# STM32H743x register map
File version: 1.0
CPU: CM7 r0p1, little endian, MPU, FPU, 4 interrupt priority bits
Registers are 32-bit, read-write, reset 0x0 unless marked. A register's access mark holds for its fields unless they carry their own. Offsets are from the block's base; [hi:lo] are bit positions; {n}, {i} and the like mark numbered series; 'fields as' and 'values as' point back to an identical list.

## RTC
Base 0x58004000
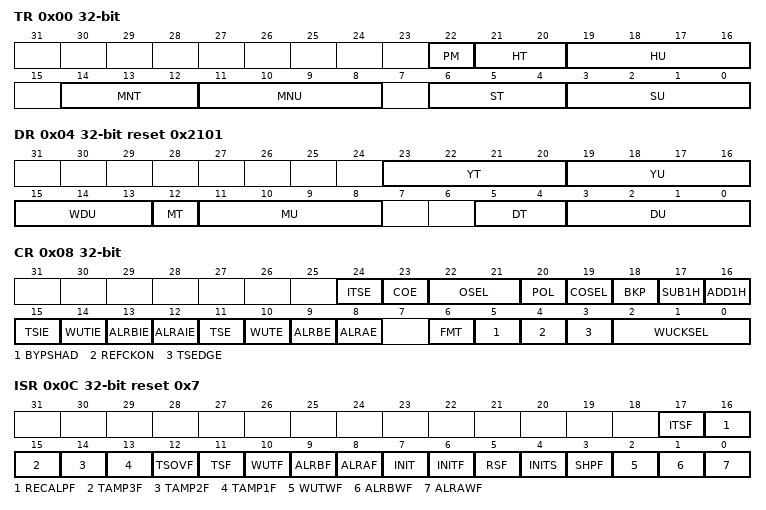
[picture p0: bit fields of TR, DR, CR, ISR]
0x00 TR — The RTC_TR is the calendar time shadow register. This register must be written in initialization mode only. Refer to Calendar initialization and configuration on page9 and Reading the calendar on page10.This register is write protected. The write access procedure is described in RTC register write protection on page9.
  [22] PM — AM/PM notation
  [21:20] HT — Hour tens in BCD format
  [19:16] HU — Hour units in BCD format
  [14:12] MNT — Minute tens in BCD format
  [11:8] MNU — Minute units in BCD format
  [6:4] ST — Second tens in BCD format
  [3:0] SU — Second units in BCD format
0x04 DR reset 0x2101 — The RTC_DR is the calendar date shadow register. This register must be written in initialization mode only. Refer to Calendar initialization and configuration on page9 and Reading the calendar on page10.This register is write protected. The write access procedure is described in RTC register write protection on page9.
  [23:20] YT — Year tens in BCD format
  [19:16] YU — Year units in BCD format
  [15:13] WDU — Week day units
  [12] MT — Month tens in BCD format
  [11:8] MU — Month units in BCD format
  [5:4] DT — Date tens in BCD format
  [3:0] DU — Date units in BCD format
0x08 CR access per field — RTC control register
  [24] ITSE rw — timestamp on internal event enable
  [23] COE rw — Calibration output enable This bit enables the RTC_CALIB output
  [22:21] OSEL rw — Output selection These bits are used to select the flag to be routed to RTC_ALARM output
  [20] POL rw — Output polarity This bit is used to configure the polarity of RTC_ALARM output
  [19] COSEL rw — Calibration output selection When COE=1, this bit selects which signal is output on RTC_CALIB. These frequencies are valid for RTCCLK at 32.768 kHz and prescalers at their default values (PREDIV_A=127 and PREDIV_S=255). Refer to Section24.3.15: Calibration clock output
  [18] BKP rw — Backup This bit can be written by the user to memorize whether the daylight saving time change has been performed or not.
  [17] SUB1H wo — Subtract 1 hour (winter time change) When this bit is set outside initialization mode, 1 hour is subtracted to the calendar time if the current hour is not 0. This bit is always read as 0. Setting this bit has no effect when current hour is 0.
  [16] ADD1H wo — Add 1 hour (summer time change) When this bit is set outside initialization mode, 1 hour is added to the calendar time. This bit is always read as 0.
  [15] TSIE rw — Time-stamp interrupt enable
  [14] WUTIE rw — Wakeup timer interrupt enable
  [13] ALRBIE rw — Alarm B interrupt enable
  [12] ALRAIE rw — Alarm A interrupt enable
  [11] TSE rw — timestamp enable
  [10] WUTE rw — Wakeup timer enable
  [9] ALRBE rw — Alarm B enable
  [8] ALRAE rw — Alarm A enable
  [6] FMT rw — Hour format
  [5] BYPSHAD rw — Bypass the shadow registers Note: If the frequency of the APB clock is less than seven times the frequency of RTCCLK, BYPSHAD must be set to 1.
  [4] REFCKON rw — RTC_REFIN reference clock detection enable (50 or 60Hz) Note: PREDIV_S must be 0x00FF.
  [3] TSEDGE rw — Time-stamp event active edge TSE must be reset when TSEDGE is changed to avoid unwanted TSF setting.
  [2:0] WUCKSEL rw — Wakeup clock selection
0x0C ISR access per field reset 0x7 — This register is write protected (except for RTC_ISR[13:8] bits). The write access procedure is described in RTC register write protection on page9.
  [17] ITSF rw — Internal tTime-stamp flag
  [16] RECALPF ro — Recalibration pending Flag The RECALPF status flag is automatically set to 1 when software writes to the RTC_CALR register, indicating that the RTC_CALR register is blocked. When the new calibration settings are taken into account, this bit returns to 0. Refer to Re-calibration on-the-fly.
  [15] TAMP3F rw — RTC_TAMP3 detection flag This flag is set by hardware when a tamper detection event is detected on the RTC_TAMP3 input. It is cleared by software writing 0
  [14] TAMP2F rw — RTC_TAMP2 detection flag This flag is set by hardware when a tamper detection event is detected on the RTC_TAMP2 input. It is cleared by software writing 0
  [13] TAMP1F rw — RTC_TAMP1 detection flag This flag is set by hardware when a tamper detection event is detected on the RTC_TAMP1 input. It is cleared by software writing 0
  [12] TSOVF rw — Time-stamp overflow flag This flag is set by hardware when a time-stamp event occurs while TSF is already set. This flag is cleared by software by writing 0. It is recommended to check and then clear TSOVF only after clearing the TSF bit. Otherwise, an overflow might not be noticed if a time-stamp event occurs immediately before the TSF bit is cleared.
  [11] TSF rw — Time-stamp flag This flag is set by hardware when a time-stamp event occurs. This flag is cleared by software by writing 0.
  [10] WUTF rw — Wakeup timer flag This flag is set by hardware when the wakeup auto-reload counter reaches 0. This flag is cleared by software by writing 0. This flag must be cleared by software at least 1.5 RTCCLK periods before WUTF is set to 1 again.
  [9] ALRBF rw — Alarm B flag This flag is set by hardware when the time/date registers (RTC_TR and RTC_DR) match the Alarm B register (RTC_ALRMBR). This flag is cleared by software by writing 0.
  [8] ALRAF rw — Alarm A flag This flag is set by hardware when the time/date registers (RTC_TR and RTC_DR) match the Alarm A register (RTC_ALRMAR). This flag is cleared by software by writing 0.
  [7] INIT rw — Initialization mode
  [6] INITF ro — Initialization flag When this bit is set to 1, the RTC is in initialization state, and the time, date and prescaler registers can be updated.
  [5] RSF rw — Registers synchronization flag This bit is set by hardware each time the calendar registers are copied into the shadow registers (RTC_SSRx, RTC_TRx and RTC_DRx). This bit is cleared by hardware in initialization mode, while a shift operation is pending (SHPF=1), or when in bypass shadow register mode (BYPSHAD=1). This bit can also be cleared by software. It is cleared either by software or by hardware in initialization mode.
  [4] INITS ro — Initialization status flag This bit is set by hardware when the calendar year field is different from 0 (Backup domain reset state).
  [3] SHPF ro — Shift operation pending This flag is set by hardware as soon as a shift operation is initiated by a write to the RTC_SHIFTR register. It is cleared by hardware when the corresponding shift operation has been executed. Writing to the SHPF bit has no effect.
  [2] WUTWF ro — Wakeup timer write flag This bit is set by hardware up to 2 RTCCLK cycles after the WUTE bit has been set to 0 in RTC_CR, and is cleared up to 2 RTCCLK cycles after the WUTE bit has been set to 1. The wakeup timer values can be changed when WUTE bit is cleared and WUTWF is set.
  [1] ALRBWF ro — Alarm B write flag This bit is set by hardware when Alarm B values can be changed, after the ALRBE bit has been set to 0 in RTC_CR. It is cleared by hardware in initialization mode.
  [0] ALRAWF ro — Alarm A write flag This bit is set by hardware when Alarm A values can be changed, after the ALRAE bit has been set to 0 in RTC_CR. It is cleared by hardware in initialization mode.
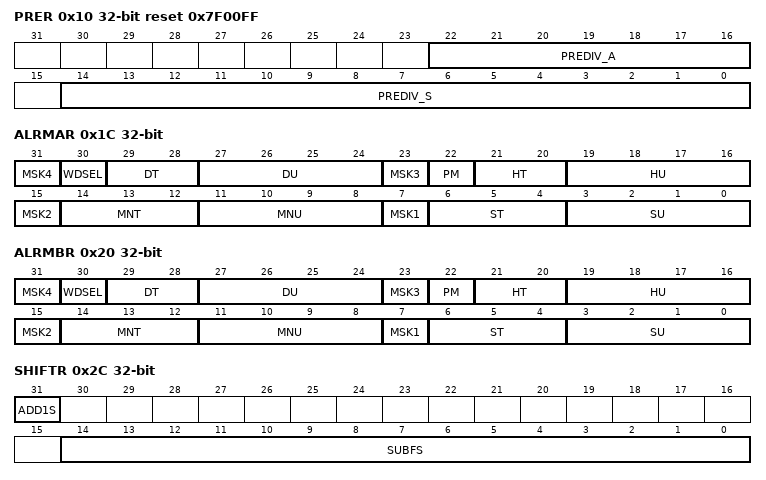
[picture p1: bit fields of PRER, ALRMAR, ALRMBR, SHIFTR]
0x10 PRER reset 0x7F00FF — This register must be written in initialization mode only. The initialization must be performed in two separate write accesses. Refer to Calendar initialization and configuration on page9.This register is write protected. The write access procedure is described in RTC register write protection on page9.
  [22:16] PREDIV_A — Asynchronous prescaler factor This is the asynchronous division factor: ck_apre frequency = RTCCLK frequency/(PREDIV_A+1)
  [14:0] PREDIV_S — Synchronous prescaler factor This is the synchronous division factor: ck_spre frequency = ck_apre frequency/(PREDIV_S+1)
0x14 WUTR reset 0xFFFF — This register can be written only when WUTWF is set to 1 in RTC_ISR.This register is write protected. The write access procedure is described in RTC register write protection on page9.
  [15:0] WUT — Wakeup auto-reload value bits When the wakeup timer is enabled (WUTE set to 1), the WUTF flag is set every (WUT[15:0] + 1) ck_wut cycles. The ck_wut period is selected through WUCKSEL[2:0] bits of the RTC_CR register When WUCKSEL[2] = 1, the wakeup timer becomes 17-bits and WUCKSEL[1] effectively becomes WUT[16] the most-significant bit to be reloaded into the timer. The first assertion of WUTF occurs (WUT+1) ck_wut cycles after WUTE is set. Setting WUT[15:0] to 0x0000 with WUCKSEL[2:0] =011 (RTCCLK/2) is forbidden.
0x1C ALRMAR — This register can be written only when ALRAWF is set to 1 in RTC_ISR, or in initialization mode.This register is write protected. The write access procedure is described in RTC register write protection on page9.
  [31] MSK4 — Alarm A date mask
  [30] WDSEL — Week day selection
  [29:28] DT — Date tens in BCD format.
  [27:24] DU — Date units or day in BCD format.
  [23] MSK3 — Alarm A hours mask
  [22] PM — AM/PM notation
  [21:20] HT — Hour tens in BCD format.
  [19:16] HU — Hour units in BCD format.
  [15] MSK2 — Alarm A minutes mask
  [14:12] MNT — Minute tens in BCD format.
  [11:8] MNU — Minute units in BCD format.
  [7] MSK1 — Alarm A seconds mask
  [6:4] ST — Second tens in BCD format.
  [3:0] SU — Second units in BCD format.
0x20 ALRMBR — This register can be written only when ALRBWF is set to 1 in RTC_ISR, or in initialization mode.This register is write protected. The write access procedure is described in RTC register write protection on page9.
  [31] MSK4 — Alarm B date mask
  [30] WDSEL — Week day selection
  [29:28] DT — Date tens in BCD format
  [27:24] DU — Date units or day in BCD format
  [23] MSK3 — Alarm B hours mask
  [22] PM — AM/PM notation
  [21:20] HT — Hour tens in BCD format
  [19:16] HU — Hour units in BCD format
  [15] MSK2 — Alarm B minutes mask
  [14:12] MNT — Minute tens in BCD format
  [11:8] MNU — Minute units in BCD format
  [7] MSK1 — Alarm B seconds mask
  [6:4] ST — Second tens in BCD format
  [3:0] SU — Second units in BCD format
0x24 WPR wo — RTC write protection register
  [7:0] KEY — Write protection key This byte is written by software. Reading this byte always returns 0x00. Refer to RTC register write protection for a description of how to unlock RTC register write protection.
0x28 SSR ro — RTC sub second register
  [15:0] SS — Sub second value SS[15:0] is the value in the synchronous prescaler counter. The fraction of a second is given by the formula below: Second fraction = (PREDIV_S - SS) / (PREDIV_S + 1) Note: SS can be larger than PREDIV_S only after a shift operation. In that case, the correct time/date is one second less than as indicated by RTC_TR/RTC_DR.
0x2C SHIFTR wo — This register is write protected. The write access procedure is described in RTC register write protection on page9.
  [31] ADD1S — Add one second This bit is write only and is always read as zero. Writing to this bit has no effect when a shift operation is pending (when SHPF=1, in RTC_ISR). This function is intended to be used with SUBFS (see description below) in order to effectively add a fraction of a second to the clock in an atomic operation.
  [14:0] SUBFS — Subtract a fraction of a second These bits are write only and is always read as zero. Writing to this bit has no effect when a shift operation is pending (when SHPF=1, in RTC_ISR). The value which is written to SUBFS is added to the synchronous prescaler counter. Since this counter counts down, this operation effectively subtracts from (delays) the clock by: Delay (seconds) = SUBFS / (PREDIV_S + 1) A fraction of a second can effectively be added to the clock (advancing the clock) when the ADD1S function is used in conjunction with SUBFS, effectively advancing the clock by: Advance (seconds) = (1 - (SUBFS / (PREDIV_S + 1))). Note: Writing to SUBFS causes RSF to be cleared. Software can then wait until RSF=1 to be sure that the shadow registers have been updated with the shifted time.
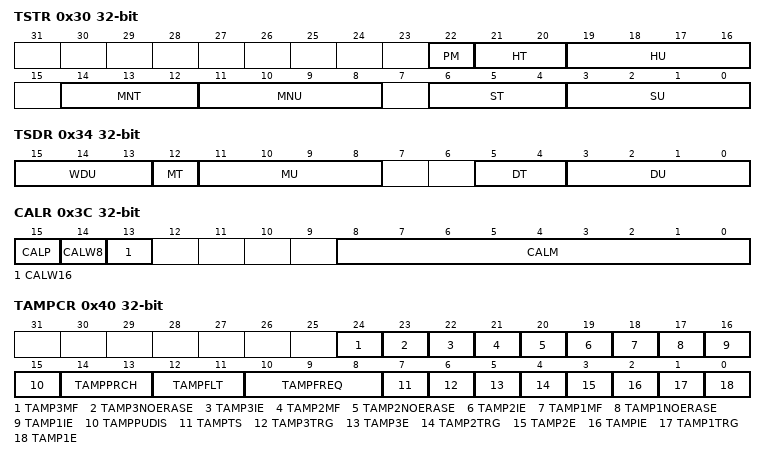
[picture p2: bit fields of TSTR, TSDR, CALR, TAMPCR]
0x30 TSTR ro — The content of this register is valid only when TSF is set to 1 in RTC_ISR. It is cleared when TSF bit is reset.
  [22] PM — AM/PM notation
  [21:20] HT — Hour tens in BCD format.
  [19:16] HU — Hour units in BCD format.
  [14:12] MNT — Minute tens in BCD format.
  [11:8] MNU — Minute units in BCD format.
  [6:4] ST — Second tens in BCD format.
  [3:0] SU — Second units in BCD format.
0x34 TSDR ro — The content of this register is valid only when TSF is set to 1 in RTC_ISR. It is cleared when TSF bit is reset.
  [15:13] WDU — Week day units
  [12] MT — Month tens in BCD format
  [11:8] MU — Month units in BCD format
  [5:4] DT — Date tens in BCD format
  [3:0] DU — Date units in BCD format
0x38 TSSSR ro — The content of this register is valid only when RTC_ISR/TSF is set. It is cleared when the RTC_ISR/TSF bit is reset.
  [15:0] SS — Sub second value SS[15:0] is the value of the synchronous prescaler counter when the timestamp event occurred.
0x3C CALR — This register is write protected. The write access procedure is described in RTC register write protection on page9.
  [15] CALP — Increase frequency of RTC by 488.5 ppm This feature is intended to be used in conjunction with CALM, which lowers the frequency of the calendar with a fine resolution. if the input frequency is 32768 Hz, the number of RTCCLK pulses added during a 32-second window is calculated as follows: (512 * CALP) - CALM. Refer to Section24.3.12: RTC smooth digital calibration.
  [14] CALW8 — Use an 8-second calibration cycle period When CALW8 is set to 1, the 8-second calibration cycle period is selected. Note: CALM[1:0] are stuck at 00; when CALW8= 1. Refer to Section24.3.12: RTC smooth digital calibration.
  [13] CALW16 — Use a 16-second calibration cycle period When CALW16 is set to 1, the 16-second calibration cycle period is selected.This bit must not be set to 1 if CALW8=1. Note: CALM[0] is stuck at 0 when CALW16= 1. Refer to Section24.3.12: RTC smooth digital calibration.
  [8:0] CALM — Calibration minus The frequency of the calendar is reduced by masking CALM out of 220 RTCCLK pulses (32 seconds if the input frequency is 32768 Hz). This decreases the frequency of the calendar with a resolution of 0.9537 ppm. To increase the frequency of the calendar, this feature should be used in conjunction with CALP. See Section24.3.12: RTC smooth digital calibration on page13.
0x40 TAMPCR — RTC tamper and alternate function configuration register
  [24] TAMP3MF — Tamper 3 mask flag
  [23] TAMP3NOERASE — Tamper 3 no erase
  [22] TAMP3IE — Tamper 3 interrupt enable
  [21] TAMP2MF — Tamper 2 mask flag
  [20] TAMP2NOERASE — Tamper 2 no erase
  [19] TAMP2IE — Tamper 2 interrupt enable
  [18] TAMP1MF — Tamper 1 mask flag
  [17] TAMP1NOERASE — Tamper 1 no erase
  [16] TAMP1IE — Tamper 1 interrupt enable
  [15] TAMPPUDIS — RTC_TAMPx pull-up disable This bit determines if each of the RTC_TAMPx pins are pre-charged before each sample.
  [14:13] TAMPPRCH — RTC_TAMPx precharge duration These bit determines the duration of time during which the pull-up/is activated before each sample. TAMPPRCH is valid for each of the RTC_TAMPx inputs.
  [12:11] TAMPFLT — RTC_TAMPx filter count These bits determines the number of consecutive samples at the specified level (TAMP*TRG) needed to activate a Tamper event. TAMPFLT is valid for each of the RTC_TAMPx inputs.
  [10:8] TAMPFREQ — Tamper sampling frequency Determines the frequency at which each of the RTC_TAMPx inputs are sampled.
  [7] TAMPTS — Activate timestamp on tamper detection event TAMPTS is valid even if TSE=0 in the RTC_CR register.
  [6] TAMP3TRG — Active level for RTC_TAMP3 input if TAMPFLT != 00: if TAMPFLT = 00:
  [5] TAMP3E — RTC_TAMP3 detection enable
  [4] TAMP2TRG — Active level for RTC_TAMP2 input if TAMPFLT != 00: if TAMPFLT = 00:
  [3] TAMP2E — RTC_TAMP2 input detection enable
  [2] TAMPIE — Tamper interrupt enable
  [1] TAMP1TRG — Active level for RTC_TAMP1 input If TAMPFLT != 00 if TAMPFLT = 00:
  [0] TAMP1E — RTC_TAMP1 input detection enable
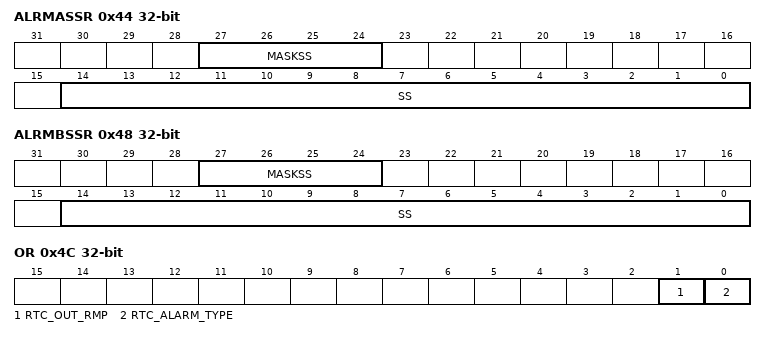
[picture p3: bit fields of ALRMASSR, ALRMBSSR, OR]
0x44 ALRMASSR — This register can be written only when ALRAE is reset in RTC_CR register, or in initialization mode.This register is write protected. The write access procedure is described in RTC register write protection on page9
  [27:24] MASKSS — Mask the most-significant bits starting at this bit ... The overflow bits of the synchronous counter (bits 15) is never compared. This bit can be different from 0 only after a shift operation.
  [14:0] SS — Sub seconds value This value is compared with the contents of the synchronous prescaler counter to determine if Alarm A is to be activated. Only bits 0 up MASKSS-1 are compared.
0x48 ALRMBSSR — This register can be written only when ALRBE is reset in RTC_CR register, or in initialization mode.This register is write protected.The write access procedure is described in Section: RTC register write protection.
  [27:24] MASKSS — Mask the most-significant bits starting at this bit ... The overflow bits of the synchronous counter (bits 15) is never compared. This bit can be different from 0 only after a shift operation.
  [14:0] SS — Sub seconds value This value is compared with the contents of the synchronous prescaler counter to determine if Alarm B is to be activated. Only bits 0 up to MASKSS-1 are compared.
0x4C OR — RTC option register
  [1] RTC_OUT_RMP — RTC_OUT remap
  [0] RTC_ALARM_TYPE — RTC_ALARM output type on PC13
{0x50+4i} BKP{i}R (i=0..7) — RTC backup registers
  [31:0] BKP — The application can write or read data to and from these registers. They are powered-on by VBAT when VDD is switched off, so that they are not reset by System reset, and their contents remain valid when the device operates in low-power mode. This register is reset on a tamper detection event, as long as TAMPxF=1. or when the Flash readout protection is disabled.
0x70 RBKP8R — RTC backup registers
  fields as BKP0R
{0x50+4i} BKP{i}R (i=9..28) — RTC backup registers
  fields as BKP0R
0xC4 _BKP29R — RTC backup registers
  fields as BKP0R
0xC8 BKP30R — RTC backup registers
  fields as BKP0R
0xCC BKP31R — RTC backup registers
  fields as BKP0R
